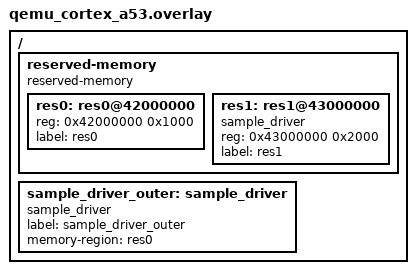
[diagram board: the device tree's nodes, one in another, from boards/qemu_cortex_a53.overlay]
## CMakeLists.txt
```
# SPDX-License-Identifier: Apache-2.0

cmake_minimum_required(VERSION 3.20.0)

find_package(Zephyr REQUIRED HINTS $ENV{ZEPHYR_BASE})
project(reserved_memory)

target_sources(app PRIVATE src/main.c)
```

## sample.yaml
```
sample:
  description: Reserved memory sample application
  name: reserved memory
tests:
  sample.board.qemu_cortex_a53.reserved_memory:
    platform_allow: qemu_cortex_a53
    tags: sample board reserved_memory
    build_only: true
```

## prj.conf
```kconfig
CONFIG_HAVE_CUSTOM_LINKER_SCRIPT=y
CONFIG_CUSTOM_LINKER_SCRIPT="linker_arm64_reserved.ld"
```

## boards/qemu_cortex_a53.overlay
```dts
/*
 * Copyright (c) 2021 Carlo Caione <ccaione@baylibre.com>
 *
 * SPDX-License-Identifier: Apache-2.0
 */

/ {
	reserved-memory {
		compatible = "reserved-memory";
		#address-cells = <1>;
		#size-cells = <1>;
		status = "okay";
		ranges;

		res0: res0@42000000 {
			reg = <0x42000000 0x1000>;
			label = "res0";
		};

		res1: res1@43000000 {
			reg = <0x43000000 0x2000>;
			compatible = "sample_driver";
			label = "res1";
		};
	};


	sample_driver_outer: sample_driver {
		compatible = "sample_driver";
		label = "sample_driver_outer";
		memory-region = <&res0>;
	};
};
```

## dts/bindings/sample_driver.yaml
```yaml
description: Sample Driver

compatible: "sample_driver"

include:
  - name: base.yaml
    property-allowlist: ['reg', 'label']

properties:
    memory-region:
      type: phandle
      required: false
      description: phandle to the reserved memory child node
```

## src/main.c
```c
/*
 * Copyright (c) 2021 Carlo Caione <ccaione@baylibre.com>
 *
 * SPDX-License-Identifier: Apache-2.0
 */

#include <zephyr/zephyr.h>
#include <zephyr/linker/linker-defs.h>

/* Variables placed in reserved sections */
uint32_t var_in_res0 __attribute((__section__(".res0"))) = 0xaabbccdd;
uint32_t var_in_res1 __attribute((__section__(".res1"))) = 0xddccbbaa;

void main(void)
{
	uint8_t *res_ptr_outer, *res_ptr_inner;
	uint32_t res_size_outer, res_size_inner;

	res_ptr_outer =
		LINKER_DT_RESERVED_MEM_GET_PTR_BY_PHANDLE(DT_NODELABEL(sample_driver_outer),
							  memory_region);
	res_size_outer =
		LINKER_DT_RESERVED_MEM_GET_SIZE_BY_PHANDLE(DT_NODELABEL(sample_driver_outer),
							   memory_region);

	printk("Reserved memory address for the outer driver: %p\n", res_ptr_outer);
	printk("Reserved memory size for the outer driver: %d\n", res_size_outer);

	res_ptr_inner = LINKER_DT_RESERVED_MEM_GET_PTR(DT_NODELABEL(res1));
	res_size_inner = LINKER_DT_RESERVED_MEM_GET_SIZE(DT_NODELABEL(res1));

	printk("Reserved memory address for the inner driver: %p\n", res_ptr_inner);
	printk("Reserved memory size for the inner driver: %d\n", res_size_inner);

	printk("Address of var_in_res0: %p\n", &var_in_res0);
	printk("Address of var_in_res1: %p\n", &var_in_res1);
}
```
